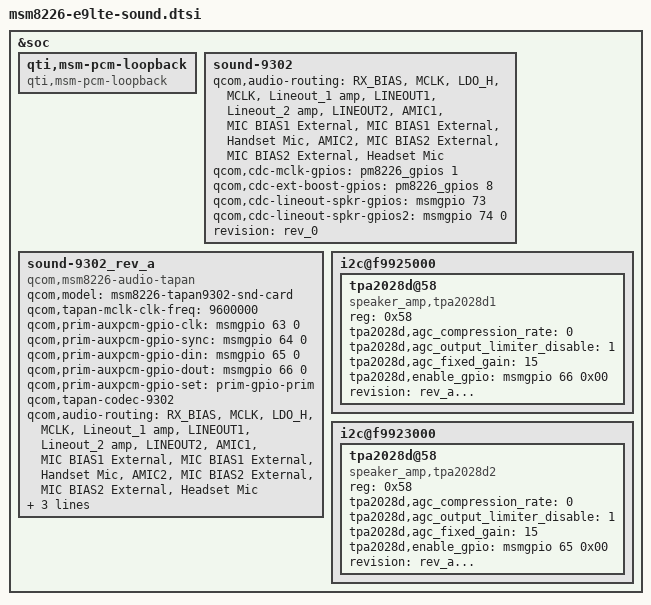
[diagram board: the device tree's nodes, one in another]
/* Copyright (c) 2012, Code Aurora Forum. All rights reserved.
 *
 * This program is free software; you can redistribute it and/or modify
 * it under the terms of the GNU General Public License version 2 and
 * only version 2 as published by the Free Software Foundation.
 *
 * This program is distributed in the hope that it will be useful,
 * but WITHOUT ANY WARRANTY; without even the implied warranty of
 * MERCHANTABILITY or FITNESS FOR A PARTICULAR PURPOSE.  See the
 * GNU General Public License for more details.
 */

&soc {
	qti,msm-pcm-loopback {
		compatible = "qti,msm-pcm-loopback";
	};
	sound-9302 {
		qcom,audio-routing =
			"RX_BIAS", "MCLK",
			"LDO_H", "MCLK",
			"Lineout_1 amp", "LINEOUT1",
			"Lineout_2 amp", "LINEOUT2",
			"AMIC1", "MIC BIAS1 External",
			"MIC BIAS1 External", "Handset Mic",
			"AMIC2", "MIC BIAS2 External",
			"MIC BIAS2 External", "Headset Mic";
		qcom,cdc-mclk-gpios = <&pm8226_gpios 1 0>;
		qcom,cdc-ext-boost-gpios = <&pm8226_gpios 8 0>;
		qcom,cdc-lineout-spkr-gpios = <&msmgpio 73 0>;
		qcom,cdc-lineout-spkr-gpios2 = <&msmgpio 74 0>;
		status = "ok";
		revision = "rev_0";
	};
	sound-9302_rev_a {
        compatible = "qcom,msm8226-audio-tapan";
        qcom,model = "msm8226-tapan9302-snd-card";
        qcom,tapan-mclk-clk-freq = <9600000>;
		qcom,prim-auxpcm-gpio-clk  = <&msmgpio 63 0>;
		qcom,prim-auxpcm-gpio-sync = <&msmgpio 64 0>;
		qcom,prim-auxpcm-gpio-din  = <&msmgpio 65 0>;
		qcom,prim-auxpcm-gpio-dout = <&msmgpio 66 0>;
		qcom,prim-auxpcm-gpio-set = "prim-gpio-prim";
        qcom,tapan-codec-9302;
		qcom,audio-routing =
			"RX_BIAS", "MCLK",
			"LDO_H", "MCLK",
			"Lineout_1 amp", "LINEOUT1",
			"Lineout_2 amp", "LINEOUT2",
			"AMIC1", "MIC BIAS1 External",
			"MIC BIAS1 External", "Handset Mic",
			"AMIC2", "MIC BIAS2 External",
			"MIC BIAS2 External", "Headset Mic";
		qcom,cdc-mclk-gpios = <&pm8226_gpios 1 0>;
		qcom,cdc-ext-boost-gpios = <&pm8226_gpios 8 0>;
		status = "ok";
		revision = "rev_a...";
       };
	i2c@f9925000 { /* BLSP1 QUP3 */
		tpa2028d@58 {
			compatible = "speaker_amp,tpa2028d1";
			status = "ok";
			reg = <0x58>;
			tpa2028d,agc_compression_rate = <0>;
			tpa2028d,agc_output_limiter_disable = <1>;
			tpa2028d,agc_fixed_gain = <15>;
			tpa2028d,enable_gpio = <&msmgpio 66 0x00>;
			revision = "rev_a...";
		};
	};
	i2c@f9923000 { /* BLSP1 QUP0 */
		tpa2028d@58 {
			compatible = "speaker_amp,tpa2028d2";
			status = "ok";
			reg = <0x58>;
			tpa2028d,agc_compression_rate = <0>;
			tpa2028d,agc_output_limiter_disable = <1>;
			tpa2028d,agc_fixed_gain = <15>;
			tpa2028d,enable_gpio = <&msmgpio 65 0x00>;
			revision = "rev_a...";
		};
	};
};
